# STM32WBA54 register map
File version: 1.0
CPU: CM33 r0p1, little endian, MPU, FPU, 4 interrupt priority bits
Registers are 32-bit, read-write, reset 0x0 unless marked. A register's access mark holds for its fields unless they carry their own. Offsets are from the block's base; [hi:lo] are bit positions.

## RCC (part 2 of 3) — Reset and clock control
Base 0x46020C00
Same registers: SEC_RCC 0x56020C00
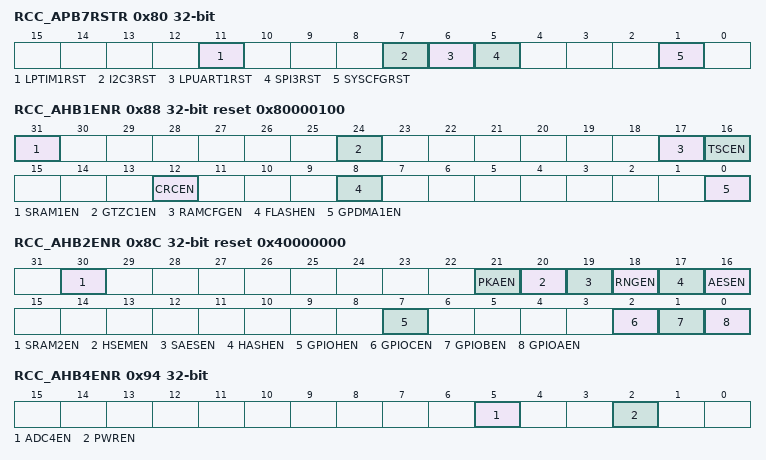
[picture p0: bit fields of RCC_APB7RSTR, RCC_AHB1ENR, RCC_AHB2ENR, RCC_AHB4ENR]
0x80 RCC_APB7RSTR — RCC APB7 peripheral reset register
  [11] LPTIM1RST — LPTIM1 reset Set and cleared by software. Access can be secured by GTZC_TZSC LPTIM1SEC. When secure, a non-secure read/write access is RAZ/WI. It does not generate an illegal access interrupt. This bit can be protected against unprivileged access when secure with RCC SPRIV or when non-secure with RCC NSPRIV.
    0=No effect; 1=Reset LPTIM1
  [7] I2C3RST — I2C3 reset Set and cleared by software. Access can be secured by GTZC_TZSC I2C3SEC. When secure, a non-secure read/write access is RAZ/WI. It does not generate an illegal access interrupt. This bit can be protected against unprivileged access when secure with RCC SPRIV or when non-secure with RCC NSPRIV.
    0=No effect; 1=Reset I2C3
  [6] LPUART1RST — LPUART1 reset Set and cleared by software. Access can be secured by GTZC_TZSC LPUART1SEC. When secure, a non-secure read/write access is RAZ/WI. It does not generate an illegal access interrupt. This bit can be protected against unprivileged access when secure with RCC SPRIV or when non-secure with RCC NSPRIV.
    0=No effect; 1=Reset LPUART1
  [5] SPI3RST — SPI3 reset Set and cleared by software. Access can be secured by GTZC_TZSC SPI3SEC. When secure, a non-secure read/write access is RAZ/WI. It does not generate an illegal access interrupt. This bit can be protected against unprivileged access when secure with RCC SPRIV or when non-secure with RCC NSPRIV.
    0=No effect; 1=Reset SPI3
  [1] SYSCFGRST — SYSCFG reset Set and cleared by software. Access can be secured by SYSCFG SYSCFGSEC. When secure, a non-secure read/write access is RAZ/WI. It does not generate an illegal access interrupt. This bit can be protected against unprivileged access when secure with RCC SPRIV or when non-secure with RCC NSPRIV.
    0=No effect; 1=Reset SYSCFG
0x88 RCC_AHB1ENR reset 0x80000100 — RCC AHB1 peripheral clock enable register
  [31] SRAM1EN — SRAM1 bus clock enable Set and reset by software. Access can be secured by GTZC_MPCBB1 SECx, INVSECSTATE. When secure, a non-secure read/write access is RAZ/WI. It does not generate an illegal access interrupt. This bit can be protected against unprivileged access when secure with RCC SPRIV or when non-secure with RCC NSPRIV.
    0=SRAM1 bus clock disabled; 1=SRAM1 bus clock enabled
  [24] GTZC1EN — GTZC1 bus clock enable Set and reset by software. Can only be accessed secure when device is secure (TZEN = 1). When secure, a non-secure read/write access is RAZ/WI. It does not generate an illegal access interrupt. This bit can be protected against unprivileged access when secure with RCC SPRIV or when non-secure with RCC NSPRIV.
    0=GTZC1 bus clock disabled; 1=GTZC1 bus clock enabled
  [17] RAMCFGEN — RAMCFG bus clock enable Set and cleared by software. Access can be secured by GTZC_TZSC RAMCFGSEC. When secure, a non-secure read/write access is RAZ/WI. It does not generate an illegal access interrupt. This bit can be protected against unprivileged access when secure with RCC SPRIV or when non-secure with RCC NSPRIV.
    0=RAMCFG bus clock disabled; 1=RAMCFG bus clock enabled
  [16] TSCEN — Touch sensing controller bus clock enable Set and cleared by software. Access can be secured by GTZC_TZSC TSCSEC. When secure, a non-secure read/write access is RAZ/WI. It does not generate an illegal access interrupt. This bit can be protected against unprivileged access when secure with RCC SPRIV or when non-secure with RCC NSPRIV.
    0=TSC bus clock disabled; 1=TSC bus clock enabled
  [12] CRCEN — CRC bus clock enable Set and cleared by software. Access can be secured by GTZC_TZSC CRCSEC. When secure, a non-secure read/write access is RAZ/WI. It does not generate an illegal access interrupt. This bit can be protected against unprivileged access when secure with RCC SPRIV or when non-secure with RCC NSPRIV.
    0=CRC bus clock disabled; 1=CRC bus clock enabled
  [8] FLASHEN — FLASH bus clock enable Set and cleared by software. This bit can be disabled only when the Flash memory is in power down mode. Can only be accessed secured when the Flash security state is secure. When secure, a non-secure read/write access is RAZ/WI. It does not generate an illegal access interrupt. This bit can be protected against unprivileged access when secure with RCC SPRIV or when non-secure with RCC NSPRIV.
    0=FLASH bus clock disabled; 1=FLASH bus clock enabled
  [0] GPDMA1EN — GPDMA1 bus clock enable Set and cleared by software. Access can be secured by GPDMA1 SECx. When secure, a non-secure read/write access is RAZ/WI. It does not generate an illegal access interrupt. This bit can be protected against unprivileged access when secure with RCC SPRIV or when non-secure with RCC NSPRIV.
    0=GPDMA1 bus clock disabled; 1=GPDMA1 bus clock enabled
0x8C RCC_AHB2ENR reset 0x40000000 — RCC AHB2 peripheral clock enable register
  [30] SRAM2EN — SRAM2 bus clock enable Set and cleared by software. Access can be secured by GTZC_MPCBB2 SECx, INVSECSTATE. When secure, a non-secure read/write access is RAZ/WI. It does not generate an illegal access interrupt. This bit can be protected against unprivileged access when secure with RCC SPRIV or when non-secure with RCC NSPRIV.
    0=SRAM2 bus clock disabled; 1=SRAM2 bus clock enabled
  [21] PKAEN — PKA bus clock enable Set and cleared by software. Access can be secured by GTZC_TZSC PKASEC. When secure, a non-secure read/write access is RAZ/WI. It does not generate an illegal access interrupt. This bit can be protected against unprivileged access when secure with RCC SPRIV or when non-secure with RCC NSPRIV.
    0=PKA bus clock disabled; 1=PKA bus clock enabled
  [20] HSEMEN — HSEM bus clock enable Set and cleared by software. Can only be accessed secure when one or more features in the HSEM is secure. When secure, a non-secure read/write access is RAZ/WI. It does not generate an illegal access interrupt. This bit can be protected against unprivileged access when secure with RCC SPRIV or when non-secure with RCC NSPRIV.
    0=HSEM bus clock disabled; 1=HSEM bus clock enabled
  [19] SAESEN — SAES bus clock enable Set and cleared by software. Access can be secured by GTZC_TZSC SAESSEC. When secure, a non-secure read/write access is RAZ/WI. It does not generate an illegal access interrupt. This bit can be protected against unprivileged access when secure with RCC SPRIV or when non-secure with RCC NSPRIV.
    0=SAES bus clock disabled; 1=SAES bus clock enabled
  [18] RNGEN — RNG bus and kernel clocks enable Set and cleared by software. Access can be secured by GTZC_TZSC RNGSEC. When secure, a non-secure read/write access is RAZ/WI. It does not generate an illegal access interrupt. This bit can be protected against unprivileged access when secure with RCC SPRIV or when non-secure with RCC NSPRIV.
    0=RNG bus and kernel clocks disabled; 1=RNG bus and kernel clocks enabled
  [17] HASHEN — HASH bus clock enable Set and cleared by software. Access can be secured by GTZC_TZSC HASHSEC. When secure, a non-secure read/write access is RAZ/WI. It does not generate an illegal access interrupt. This bit can be protected against unprivileged access when secure with RCC SPRIV or when non-secure with RCC NSPRIV.
    0=HASH bus clock disabled; 1=HASH bus clock enabled
  [16] AESEN — AES bus clock enable Set and cleared by software. Access can be secured by GTZC_TZSC AESSEC. When secure, a non-secure read/write access is RAZ/WI. It does not generate an illegal access interrupt. This bit can be protected against unprivileged access when secure with RCC SPRIV or when non-secure with RCC NSPRIV.
    0=AES bus clock disabled; 1=AES bus clock enabled
  [7] GPIOHEN — IO port H bus clock enable Set and cleared by software. Access can be secured by GPIOH SECx. When secure, a non-secure read/write access is RAZ/WI. It does not generate an illegal access interrupt. This bit can be protected against unprivileged access when secure with RCC SPRIV or when non-secure with RCC NSPRIV.
    0=IO port H bus clock disabled; 1=IO port H bus clock enabled
  [2] GPIOCEN — IO port C bus clock enable Set and cleared by software. Access can be secured by GPIOC SECx. When secure, a non-secure read/write access is RAZ/WI. It does not generate an illegal access interrupt. This bit can be protected against unprivileged access when secure with RCC SPRIV or when non-secure with RCC NSPRIV.
    0=IO port C bus clock disabled; 1=IO port C bus clock enabled
  [1] GPIOBEN — IO port B bus clock enable Set and cleared by software. Access can be secured by GPIOB SECx. When secure, a non-secure read/write access is RAZ/WI. It does not generate an illegal access interrupt. This bit can be protected against unprivileged access when secure with RCC SPRIV or when non-secure with RCC NSPRIV.
    0=IO port B bus clock disabled; 1=IO port B bus clock enabled
  [0] GPIOAEN — IO port A bus clock enable Set and cleared by software. Access can be secured by GPIOA SECx. When secure, a non-secure read/write access is RAZ/WI. It does not generate an illegal access interrupt. This bit can be protected against unprivileged access when secure with RCC SPRIV or when non-secure with RCC NSPRIV.
    0=IO port A bus clock disabled; 1=IO port A bus clock enabled
0x94 RCC_AHB4ENR — RCC AHB4 peripheral clock enable register
  [5] ADC4EN — ADC4 bus and kernel clocks enable Set and cleared by software. Access can be secured by GTZC_TZSC ADC4SEC. When secure, a non-secure read/write access is RAZ/WI. It does not generate an illegal access interrupt. This bit can be protected against unprivileged access when secure with RCC SPRIV or when non-secure with RCC NSPRIV.
    0=ADC4 bus and kernel clocks disabled; 1=ADC4 bus and kernel clocks enabled
  [2] PWREN — PWR bus clock enable Set and cleared by software. Can only be accessed secure when one or more features in the PWR is/are secure. When secure, a non-secure read/write access is RAZ/WI. It does not generate an illegal access interrupt. This bit can be protected against unprivileged access when secure with RCC SPRIV or when non-secure with RCC NSPRIV.
    0=PWR bus clock disabled; 1=PWR bus clock enabled
0x98 RCC_AHB5ENR — RCC AHB5 peripheral clock enable register
  [0] RADIOEN — 2.4 GHz RADIO bus clock enable Set and cleared by software. Access can be secured by GTZC_TZSC RADIOSEC. When secure, a non-secure read/write access is RAZ/WI. It does not generate an illegal access interrupt. This bit can be protected against unprivileged access when secure with RCC SPRIV or when non-secure with RCC NSPRIV. Before accessing the 2.4 GHz RADIO sleep timers registers the RADIOCLKRDY bit must be checked. Note: When RADIOSMEN and STRADIOCLKON are both cleared, RADIOCLKRDY bit must be re-checked when exiting low-power modes (Sleep and Stop).
    0=2.4 GHz RADIO bus clock disabled (The 2.4 GHz RADIO bus clock may still be enabled by STRADIOCLKON); 1=2.4 GHz RADIO bus clock enabled
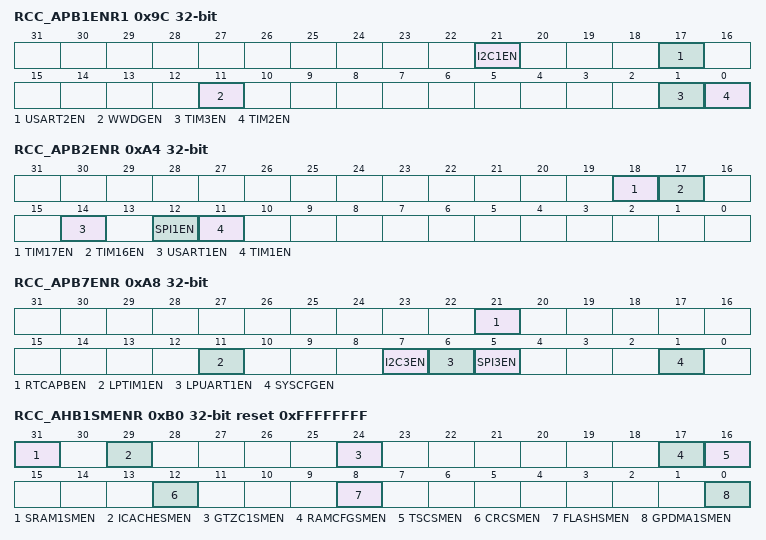
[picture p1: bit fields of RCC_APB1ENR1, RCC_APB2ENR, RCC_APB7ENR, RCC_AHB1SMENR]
0x9C RCC_APB1ENR1 — RCC APB1 peripheral clock enable register 1
  [21] I2C1EN — I2C1 bus and kernel clocks enable Set and cleared by software. Access can be secured by GTZC_TZSC I2C1SEC. When secure, a non-secure read/write access is RAZ/WI. It does not generate an illegal access interrupt. This bit can be protected against unprivileged access when secure with RCC SPRIV or when non-secure with RCC NSPRIV.
    0=I2C1 bus and kernel clocks disabled; 1=I2C1 bus and kernel clocks enabled
  [17] USART2EN — USART2 bus and kernel clocks enable Set and cleared by software. Access can be secured by GTZC_TZSC USART2SEC When secure, a non-secure read/write access is RAZ/WI. It does not generate an illegal access interrupt. This bit can be protected against unprivileged access when secure with RCC SPRIV or when non-secure with RCC NSPRIV..
    0=USART2 bus and kernel clocks disabled; 1=USART2 bus and kernel clocks enabled
  [11] WWDGEN — WWDG bus clock enable Set by software to enable the window watchdog bus clock. Reset by hardware system reset. This bit can also be set by hardware if the WWDG_SW option bit is reset. Access can be secured by GTZC_TZSC WWDGSEC. When secure, a non-secure read/write access is RAZ/WI. It does not generate an illegal access interrupt. This bit can be protected against unprivileged access when secure with RCC SPRIV or when non-secure with RCC NSPRIV.
    0=WWDG bus clock disabled; 1=WWDG bus clock enabled
  [1] TIM3EN — TIM3 bus and kernel clocks enable Set and cleared by software. Access can be secured by GTZC_TZSC TIM2SEC. When secure, a non-secure read/write access is RAZ/WI. It does not generate an illegal access interrupt. This bit can be protected against unprivileged access when secure with RCC SPRIV or when non-secure with RCC NSPRIV.
    0=TIM3 bus and kernel clocks disabled; 1=TIM3 bus and kernel clocks enabled
  [0] TIM2EN — TIM2 bus and kernel clocks enable Set and cleared by software. Access can be secured by GTZC_TZSC TIM2SEC. When secure, a non-secure read/write access is RAZ/WI. It does not generate an illegal access interrupt. This bit can be protected against unprivileged access when secure with RCC SPRIV or when non-secure with RCC NSPRIV.
    0=TIM2 bus and kernel clocks disabled; 1=TIM2 bus and kernel clocks enabled
0xA0 RCC_APB1ENR2 — RCC APB1 peripheral clock enable register 2
  [5] LPTIM2EN — LPTIM2 bus and kernel clocks enable Set and cleared by software. Access can be secured by GTZC_TZSC LPTIM2SEC. When secure, a non-secure read/write access is RAZ/WI. It does not generate an illegal access interrupt. This bit can be protected against unprivileged access when secure with RCC SPRIV or when non-secure with RCC NSPRIV.
    0=LPTIM2 bus and kernel clocks disabled; 1=LPTIM2 bus and kernel clocks enabled
0xA4 RCC_APB2ENR — RCC APB2 peripheral clock enable register
  [18] TIM17EN — TIM17 bus and kernel clocks enable Set and cleared by software. Access can be secured by GTZC_TZSC TIM17SEC. When secure, a non-secure read/write access is RAZ/WI. It does not generate an illegal access interrupt. This bit can be protected against unprivileged access when secure with RCC SPRIV or when non-secure with RCC NSPRIV.
    0=TIM17 bus and kernel clocks disabled; 1=TIM17 bus and kernel clocks enabled
  [17] TIM16EN — TIM16 bus and kernel clocks enable Set and cleared by software. Access can be secured by GTZC_TZSC TIM16SEC. When secure, a non-secure read/write access is RAZ/WI. It does not generate an illegal access interrupt. This bit can be protected against unprivileged access when secure with RCC SPRIV or when non-secure with RCC NSPRIV.
    0=TIM16 bus and kernel clocks disabled; 1=TIM16 bus and kernel clocks enabled
  [14] USART1EN — USART1bus and kernel clocks enable Set and cleared by software. Access can be secured by GTZC_TZSC USART1SEC. When secure, a non-secure read/write access is RAZ/WI. It does not generate an illegal access interrupt. This bit can be protected against unprivileged access when secure with RCC SPRIV or when non-secure with RCC NSPRIV.
    0=USART1 bus and kernel clocks disabled; 1=USART1 bus and kernel clocks enabled
  [12] SPI1EN — SPI1 bus and kernel clocks enable Set and cleared by software. Access can be secured by GTZC_TZSC SPI1SEC. When secure, a non-secure read/write access is RAZ/WI. It does not generate an illegal access interrupt. This bit can be protected against unprivileged access when secure with RCC SPRIV or when non-secure with RCC NSPRIV.
    0=SPI1 bus and kernel clocks disabled; 1=SPI1 bus and kernel clocks enabled
  [11] TIM1EN — TIM1 bus and kernel clocks enable Set and cleared by software. Access can be secured by GTZC_TZSC TIM1SEC. When secure, a non-secure read/write access is RAZ/WI. It does not generate an illegal access interrupt. This bit can be protected against unprivileged access when secure with RCC SPRIV or when non-secure with RCC NSPRIV.
    0=TIM1 bus and kernel clocks disabled; 1=TIM1 bus and kernel clocks enabled
0xA8 RCC_APB7ENR — RCC APB7 peripheral clock enable register
  [21] RTCAPBEN — RTC and TAMP bus clock enable Set and cleared by software. Can only be accessed secure when one or more features in the RTC or TAMP is/are secure. When secure, a non-secure read/write access is RAZ/WI. It does not generate an illegal access interrupt. This bit can be protected against unprivileged access when secure with RCC SPRIV or when non-secure with RCC NSPRIV.
    0=RTC bus clock disabled; 1=RTC bus clock enabled
  [11] LPTIM1EN — LPTIM1 bus and kernel clocks enable Set and cleared by software. Access can be secured by GTZC_TZSC LPTIM1SEC. When secure, a non-secure read/write access is RAZ/WI. It does not generate an illegal access interrupt. This bit can be protected against unprivileged access when secure with RCC SPRIV or when non-secure with RCC NSPRIV.
    0=LPTIM1 bus and kernel clocks disabled; 1=LPTIM1 bus and kernel clocks enabled
  [7] I2C3EN — I2C3 bus and kernel clocks enable Set and cleared by software. Access can be secured by GTZC_TZSC I2C3SEC. When secure, a non-secure read/write access is RAZ/WI. It does not generate an illegal access interrupt. This bit can be protected against unprivileged access when secure with RCC SPRIV or when non-secure with RCC NSPRIV.
    0=I2C3 bus and kernel clocks disabled; 1=I2C3 bus and kernel clocks enabled
  [6] LPUART1EN — LPUART1 bus and kernel clocks enable Set and cleared by software. Access can be secured by GTZC_TZSC LPUART1SEC. When secure, a non-secure read/write access is RAZ/WI. It does not generate an illegal access interrupt. This bit can be protected against unprivileged access when secure with RCC SPRIV or when non-secure with RCC NSPRIV.
    0=LPUART1 bus and kernel clocks disabled; 1=LPUART1 bus and kernel clocks enabled
  [5] SPI3EN — SPI3 bus and kernel clocks enable Set and cleared by software. Access can be secured by GTZC_TZSC SPI3SEC. When secure, a non-secure read/write access is RAZ/WI. It does not generate an illegal access interrupt. This bit can be protected against unprivileged access when secure with RCC SPRIV or when non-secure with RCC NSPRIV.
    0=SPI3 bus and kernel clocks disabled; 1=SPI3 bus and kernel clocks enabled
  [1] SYSCFGEN — SYSCFG bus clock enable Set and cleared by software. Access can be secured by SYSCFG SYSCFGSEC. When secure, a non-secure read/write access is RAZ/WI. It does not generate an illegal access interrupt. This bit can be protected against unprivileged access when secure with RCC SPRIV or when non-secure with RCC NSPRIV.
    0=SYSCFG bus clock disabled; 1=SYSCFG bus clock enabled
0xB0 RCC_AHB1SMENR reset 0xFFFFFFFF — RCC AHB1 peripheral clocks enable in Sleep and Stop modes register
  [31] SRAM1SMEN — SRAM1 bus clock enable during Sleep and Stop modes Set and cleared by software. Access can be secured by GTZC_MPCBB1 SECx, INVSECSTATE. When secure, a non-secure read/write access is RAZ/WI. It does not generate an illegal access interrupt. This bit can be protected against unprivileged access when secure with RCC SPRIV or when non-secure with RCC NSPRIV.
    0=SRAM1 bus clock disabled by the clock gating during Sleep and Stop modes; 1=SRAM1 bus clock enabled by the clock gating during Sleep and Stop modes
  [29] ICACHESMEN — ICACHE bus clock enable during Sleep and Stop modes Set and cleared by software. Access can be secured by GTZC_TZSC ICACHE_REGSEC. When secure, a non-secure read/write access is RAZ/WI. It does not generate an illegal access interrupt. This bit can be protected against unprivileged access when secure with RCC SPRIV or when non-secure with RCC NSPRIV..
    0=ICACHE bus clock disabled by the clock gating during Sleep and Stop modes; 1=ICACHE bus clock enabled by the clock gating during Sleep and Stop modes
  [24] GTZC1SMEN — GTZC1 bus clock enable during Sleep and Stop modes Set and cleared by software. Can only be accessed secure when one device is secure (TZEN = 1). When secure, a non-secure read/write access is RAZ/WI. It does not generate an illegal access interrupt. This bit can be protected against unprivileged access when secure with RCC SPRIV or when non-secure with RCC NSPRIV.
    0=GTZC1 bus clock disabled by the clock gating during Sleep and Stop modes; 1=GTZC1 bus clock enabled by the clock gating during Sleep and Stop modes
  [17] RAMCFGSMEN — RAMCFG bus clock enable during Sleep and Stop modes Set and cleared by software. Access can be secured by GTZC_TZSC RAMCFGSEC. When secure, a non-secure read/write access is RAZ/WI. It does not generate an illegal access interrupt. This bit can be protected against unprivileged access when secure with RCC SPRIV or when non-secure with RCC NSPRIV.
    0=RAMCFG bus clock disabled by the clock gating during Sleep and Stop modes; 1=RAMCFG bus clock enabled by the clock gating during Sleep and Stop modes
  [16] TSCSMEN — TSC bus clock enable during Sleep and Stop modes Set and cleared by software. Access can be secured by GTZC_TZSC TSCSEC. When secure, a non-secure read/write access is RAZ/WI. It does not generate an illegal access interrupt. This bit can be protected against unprivileged access when secure with RCC SPRIV or when non-secure with RCC NSPRIV..
    0=TSC bus clock disabled by the clock gating during Sleep and Stop modes; 1=TSC bus clock enabled by the clock gating during Sleep and Stop modes
  [12] CRCSMEN — CRC bus clock enable during Sleep and Stop modes Set and cleared by software. Access can be secured by GTZC_TZSC CRCSEC. When secure, a non-secure read/write access is RAZ/WI. It does not generate an illegal access interrupt. This bit can be protected against unprivileged access when secure with RCC SPRIV or when non-secure with RCC NSPRIV.
    0=CRC bus clock disabled by the clock gating during Sleep and Stop modes; 1=CRC bus clock enabled by the clock gating during Sleep and Stop modes
  [8] FLASHSMEN — FLASH bus clock enable during Sleep and Stop modes Set and cleared by software. Can only be accessed secured when the Flash security state is secure. When secure, a non-secure read/write access is RAZ/WI. It does not generate an illegal access interrupt. This bit can be protected against unprivileged access when secure with RCC SPRIV or when non-secure with RCC NSPRIV.
    0=FLASH bus clock disabled by the clock gating during Sleep and Stop modes; 1=FLASH bus clock enabled by the clock gating during Sleep and Stop modes
  [0] GPDMA1SMEN — GPDMA1 bus clock enable during Sleep and Stop modes Set and cleared by software. Access can be secured by GPDMA1 SECx. When secure, a non-secure read/write access is RAZ/WI. It does not generate an illegal access interrupt. This bit can be protected against unprivileged access when secure with RCC SPRIV or when non-secure with RCC NSPRIV. Note: This bit must be set to allow the peripheral to wake up from Stop modes.
    0=GPDMA1 bus clock disabled by the clock gating during Sleep and Stop modes; 1=GPDMA1 bus clock enabled by the clock gating during Sleep and Stop modes
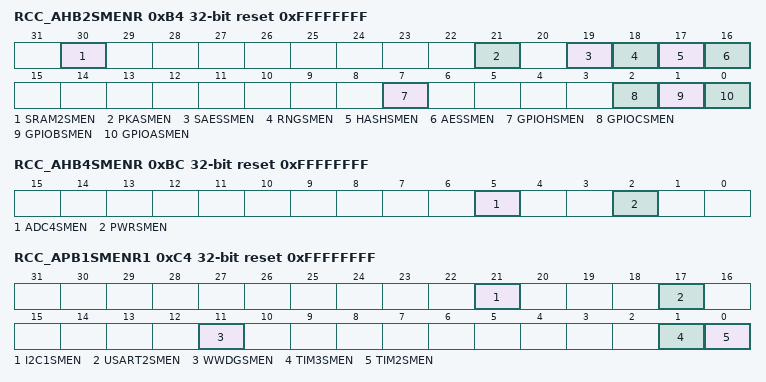
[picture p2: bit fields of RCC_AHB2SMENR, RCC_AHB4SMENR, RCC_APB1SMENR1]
0xB4 RCC_AHB2SMENR reset 0xFFFFFFFF — RCC AHB2 peripheral clocks enable in Sleep and Stop modes register
  [30] SRAM2SMEN — SRAM2 bus clock enable during Sleep and Stop modes Set and cleared by software. Access can be secured by GTZC_MPCBB2 SECx, INVSECSTATE. When secure, a non-secure read/write access is RAZ/WI. It does not generate an illegal access interrupt. This bit can be protected against unprivileged access when secure with RCC SPRIV or when non-secure with RCC NSPRIV.
    0=SRAM2 bus clock disabled by the clock gating during Sleep and Stop modes; 1=SRAM2 bus clock enabled by the clock gating during Sleep and Stop modes
  [21] PKASMEN — PKA bus clock enable during Sleep and Stop modes Set and cleared by software. Access can be secured by GTZC_TZSC PKASEC. When secure, a non-secure read/write access is RAZ/WI. It does not generate an illegal access interrupt. This bit can be protected against unprivileged access when secure with RCC SPRIV or when non-secure with RCC NSPRIV.
    0=PKA bus clock disabled by the clock gating during Sleep and Stop modes; 1=PKA bus clock enabled by the clock gating during Sleep and Stop modes
  [19] SAESSMEN — SAES accelerator bus clock enable during Sleep and Stop modes Set and cleared by software. Access can be secured by GTZC_TZSC SAESSEC. When secure, a non-secure read/write access is RAZ/WI. It does not generate an illegal access interrupt. This bit can be protected against unprivileged access when secure with RCC SPRIV or when non-secure with RCC NSPRIV.
    0=SAES bus clock disabled by the clock gating during Sleep and Stop modes; 1=SAES bus clock enabled by the clock gating during Sleep and Stop modes
  [18] RNGSMEN — Random number generator (RNG) bus and kernel clocks enable during Sleep and Stop modes Set and cleared by software. Access can be secured by GTZC_TZSC RNGSEC. When secure, a non-secure read/write access is RAZ/WI. It does not generate an illegal access interrupt. This bit can be protected against unprivileged access when secure with RCC SPRIV or when non-secure with RCC NSPRIV.
    0=RNG bus and kernel clocks disabled by the clock gating during Sleep and Stop modes; 1=RNG bus and kernel clocks enabled by the clock gating during Sleep and Stop modes
  [17] HASHSMEN — HASH bus clock enable during Sleep and Stop modes Set and cleared by software. Access can be secured by GTZC_TZSC HASHSEC. When secure, a non-secure read/write access is RAZ/WI. It does not generate an illegal access interrupt. This bit can be protected against unprivileged access when secure with RCC SPRIV or when non-secure with RCC NSPRIV.
    0=HASH bus clock disabled by the clock gating during Sleep and Stop modes; 1=HASH bus clock enabled by the clock gating during Sleep and Stop modes
  [16] AESSMEN — AES bus clock enable during Sleep and Stop modes Set and cleared by software. Access can be secured by GTZC_TZSC AESSEC. When secure, a non-secure read/write access is RAZ/WI. It does not generate an illegal access interrupt. This bit can be protected against unprivileged access when secure with RCC SPRIV or when non-secure with RCC NSPRIV.
    0=AES bus clock disabled by the clock gating during Sleep and Stop modes; 1=AES bus clock enabled by the clock gating during Sleep and Stop modes
  [7] GPIOHSMEN — IO port H bus clock enable during Sleep and Stop modes Set and cleared by software. Access can be secured by GPIOH SECx. When secure, a non-secure read/write access is RAZ/WI. It does not generate an illegal access interrupt. This bit can be protected against unprivileged access when secure with RCC SPRIV or when non-secure with RCC NSPRIV.
    0=IO port H bus clock disabled by the clock gating during Sleep and Stop modes; 1=IO port H bus clock enabled by the clock gating during Sleep and Stop modes
  [2] GPIOCSMEN — IO port C bus clock enable during Sleep and Stop modes Set and cleared by software. Access can be secured by GPIOC SECx. When secure, a non-secure read/write access is RAZ/WI. It does not generate an illegal access interrupt. This bit can be protected against unprivileged access when secure with RCC SPRIV or when non-secure with RCC NSPRIV.
    0=IO port C bus clock disabled by the clock gating during Sleep and Stop modes; 1=IO port C bus clock enabled by the clock gating during Sleep and Stop modes
  [1] GPIOBSMEN — IO port B bus clock enable during Sleep and Stop modes Set and cleared by software. Access can be secured by GPIOB SECx. When secure, a non-secure read/write access is RAZ/WI. It does not generate an illegal access interrupt. This bit can be protected against unprivileged access when secure with RCC SPRIV or when non-secure with RCC NSPRIV.
    0=IO port B bus clock disabled by the clock gating during Sleep and Stop modes; 1=IO port B bus clock enabled by the clock gating during Sleep and Stop modes
  [0] GPIOASMEN — IO port A bus clock enable during Sleep and Stop modes Set and cleared by software. Access can be secured by GPIOA SECx. When secure, a non-secure read/write access is RAZ/WI. It does not generate an illegal access interrupt. This bit can be protected against unprivileged access when secure with RCC SPRIV or when non-secure with RCC NSPRIV.
    0=IO port A bus clock disabled by the clock gating during Sleep and Stop modes; 1=IO port A bus clock enabled by the clock gating during Sleep and Stop modes
0xBC RCC_AHB4SMENR reset 0xFFFFFFFF — RCC AHB4 peripheral clocks enable in Sleep and Stop modes register
  [5] ADC4SMEN — ADC4 bus and kernel clocks enable during Sleep and Stop modes Set and cleared by software. Access can be secured by GTZC_TZSC ADC4SEC. When secure, a non-secure read/write access is RAZ/WI. It does not generate an illegal access interrupt. This bit can be protected against unprivileged access when secure with RCC SPRIV or when non-secure with RCC NSPRIV. Note: This bit must be set to allow the peripheral to wake up from Stop modes.
    0=ADC4 bus and kernel clocks disabled by the clock gating during Sleep and Stop modes; 1=ADC4 bus and kernel clocks enabled by the clock gating during Sleep and Stop modes
  [2] PWRSMEN — PWR bus clock enable during Sleep and Stop modes Set and cleared by software. Can only be accessed secure when one or more features in the PWR is/are secure. When secure, a non-secure read/write access is RAZ/WI. It does not generate an illegal access interrupt. This bit can be protected against unprivileged access when secure with RCC SPRIV or when non-secure with RCC NSPRIV.
    0=PWR bus clock disabled by the clock gating during Sleep and Stop modes; 1=PWR bus clock enabled by the clock gating during Sleep and Stop modes
0xC0 RCC_AHB5SMENR reset 0xFFFFFFFF — RCC AHB5 peripheral clocks enable in Sleep and Stop modes register
  [0] RADIOSMEN — 2.4 GHz RADIO bus clock enable during Sleep and Stop modes when the 2.4 GHz RADIO is active. Set and cleared by software. Access can be secured by GTZC_TZSC RADIOSEC. When secure, a non-secure read/write access is RAZ/WI. It does not generate an illegal access interrupt. This bit can be protected against unprivileged access when secure with RCC SPRIV or when non-secure with RCC NSPRIV.
    0=2.4 GHz RADIO bus clock disabled by the clock gating during Sleep and Stop modes (The 2.4 GHz RADIO bus clock may still be enabled by STRADIOCLKON); 1=2.4 GHz RADIO bus clock enabled by the clock gating during Sleep and Stop modes when the 2.4 GHz RADIO is active
0xC4 RCC_APB1SMENR1 reset 0xFFFFFFFF — RCC APB1 peripheral clocks enable in Sleep and Stop modes register 1
  [21] I2C1SMEN — I2C1 bus and kernel clocks enable during Sleep and Stop modes Set and cleared by software. Access can be secured by GTZC_TZSC I2C1SEC. When secure, a non-secure read/write access is RAZ/WI. It does not generate an illegal access interrupt. This bit can be protected against unprivileged access when secure with RCC SPRIV or when non-secure with RCC NSPRIV. Note: This bit must be set to allow the peripheral to wake up from Stop modes.
    0=I2C1 bus and kernel clocks disabled by the clock gating during Sleep and Stop modes; 1=I2C1 bus and kernel clocks enabled by the clock gating during Sleep and Stop modes
  [17] USART2SMEN — USART2 bus and kernel clocks enable during Sleep and Stop modes Set and cleared by software. Access can be secured by GTZC_TZSC USART2SEC. When secure, a non-secure read/write access is RAZ/WI. It does not generate an illegal access interrupt. This bit can be protected against unprivileged access when secure with RCC SPRIV or when non-secure with RCC NSPRIV. Note: This bit must be set to allow the peripheral to wake up from Stop modes.
    0=USART2 bus and kernel clocks disabled by the clock gating during Sleep and Stop modes; 1=USART2 bus and kernel clocks enabled by the clock gating during Sleep and Stop modes
  [11] WWDGSMEN — Window watchdog bus clock enable during Sleep and Stop modes Set and cleared by software. This bit is forced to 1 by hardware when the hardware WWDG option is activated. Access can be secured by GTZC_TZSC WWDGSEC. When secure, a non-secure read/write access is RAZ/WI. It does not generate an illegal access interrupt. This bit can be protected against unprivileged access when secure with RCC SPRIV or when non-secure with RCC NSPRIV.
    0=WWDG bus clock disabled by the clock gating during Sleep mode; 1=WWDG bus clock enabled by the clock gating during Sleep mode
  [1] TIM3SMEN — TIM3 bus and kernel clocks enable during Sleep and Stop modes Set and cleared by software. Access can be secured by GTZC_TZSC TIM3SEC. When secure, a non-secure read/write access is RAZ/WI. It does not generate an illegal access interrupt. This bit can be protected against unprivileged access when secure with RCC SPRIV or when non-secure with RCC NSPRIV.
    0=TIM3 bus and kernel clocks disabled by the clock gating during Sleep and Stop modes; 1=TIM3 bus and kernel clocks enabled by the clock gating during Sleep and Stop modes
  [0] TIM2SMEN — TIM2 bus and kernel clocks enable during Sleep and Stop modes Set and cleared by software. Access can be secured by GTZC_TZSC TIM2SEC. When secure, a non-secure read/write access is RAZ/WI. It does not generate an illegal access interrupt. This bit can be protected against unprivileged access when secure with RCC SPRIV or when non-secure with RCC NSPRIV.
    0=TIM2 bus and kernel clocks disabled by the clock gating during Sleep and Stop modes; 1=TIM2 bus and kernel clocks enabled by the clock gating during Sleep and Stop modes
